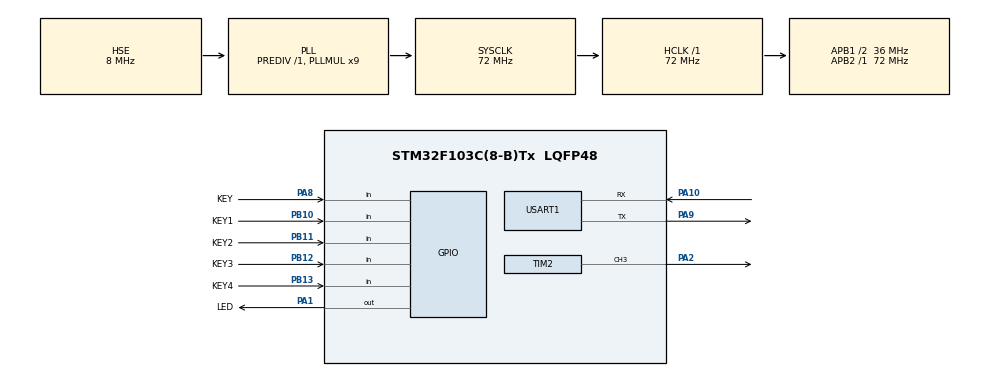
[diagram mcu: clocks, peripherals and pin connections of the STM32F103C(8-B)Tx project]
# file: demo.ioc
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Dma.Request0=TIM2_CH3
Dma.TIM2_CH3.0.Direction=DMA_MEMORY_TO_PERIPH
Dma.TIM2_CH3.0.Instance=DMA1_Channel1
Dma.TIM2_CH3.0.MemDataAlignment=DMA_MDATAALIGN_WORD
Dma.TIM2_CH3.0.MemInc=DMA_MINC_ENABLE
Dma.TIM2_CH3.0.Mode=DMA_NORMAL
Dma.TIM2_CH3.0.PeriphDataAlignment=DMA_PDATAALIGN_HALFWORD
Dma.TIM2_CH3.0.PeriphInc=DMA_PINC_DISABLE
Dma.TIM2_CH3.0.Priority=DMA_PRIORITY_LOW
Mcu.Family=STM32F1
Mcu.Name=STM32F103C(8-B)Tx
Mcu.Package=LQFP48
Mcu.UserConstants=ENC_TIM,htim4
NVIC.DMA1_Channel1_IRQn=true\:0\:0\:false\:false\:true\:false\:true\:true
NVIC.PriorityGroup=NVIC_PRIORITYGROUP_4
PA1.GPIO_Label=LED
PA1.GPIO_PuPd=GPIO_PULLUP
PA1.GPIO_Speed=GPIO_SPEED_FREQ_HIGH
PA1.Signal=GPIO_Output
PA10.Mode=Asynchronous
PA10.Signal=USART1_RX
PA13.Mode=Serial_Wire
PA13.Signal=SYS_JTMS-SWDIO
PA14.Mode=Serial_Wire
PA14.Signal=SYS_JTCK-SWCLK
PA2.Signal=S_TIM2_CH3
PA8.GPIO_Label=KEY
PA8.GPIO_PuPd=GPIO_PULLUP
PA8.Signal=GPIO_Input
PA9.Mode=Asynchronous
PA9.Signal=USART1_TX
PB10.GPIO_Label=KEY1
PB10.GPIO_PuPd=GPIO_PULLUP
PB10.Signal=GPIO_Input
PB11.GPIO_Label=KEY2
PB11.GPIO_PuPd=GPIO_PULLUP
PB11.Signal=GPIO_Input
PB12.GPIO_Label=KEY3
PB12.GPIO_PuPd=GPIO_PULLUP
PB12.Signal=GPIO_Input
PB13.GPIO_Label=KEY4
PB13.GPIO_PuPd=GPIO_PULLUP
PB13.Signal=GPIO_Input
PB9.GPIO_Speed=GPIO_SPEED_FREQ_HIGH
PB9.Signal=I2C1_SDA
PD0-OSC_IN.Mode=HSE-External-Oscillator
PD0-OSC_IN.Signal=RCC_OSC_IN
PD1-OSC_OUT.Mode=HSE-External-Oscillator
PD1-OSC_OUT.Signal=RCC_OSC_OUT
ProjectManager.HeapSize=0x800
ProjectManager.StackSize=0x800
ProjectManager.TargetToolchain=MDK-ARM V5
RCC.AHBFreq_Value=72000000
RCC.APB1CLKDivider=RCC_HCLK_DIV2
RCC.APB1Freq_Value=36000000
RCC.APB1TimFreq_Value=72000000
RCC.APB2Freq_Value=72000000
RCC.APB2TimFreq_Value=72000000
RCC.HCLKFreq_Value=72000000
RCC.PLLMUL=RCC_PLL_MUL9
RCC.PLLSourceVirtual=RCC_PLLSOURCE_HSE
RCC.SYSCLKFreq_VALUE=72000000
RCC.SYSCLKSource=RCC_SYSCLKSOURCE_PLLCLK
RCC.USBFreq_Value=48000000
RCC.USBPrescaler=RCC_USBCLKSOURCE_PLL_DIV1_5
SH.S_TIM2_CH3.0=TIM2_CH3,PWM Generation3 CH3
TIM2.AutoReloadPreload=TIM_AUTORELOAD_PRELOAD_DISABLE
TIM2.Channel-PWM\ Generation3\ CH3=TIM_CHANNEL_3
TIM2.Period=90-1
USART1.VirtualMode=VM_ASYNC
VP_RTC_VS_RTC_Activate.Mode=RTC_Enabled
board=custom

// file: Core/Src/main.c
/* USER CODE BEGIN Header */
/**
 ******************************************************************************
 * @file           : main.c
 * @brief          : Main program body
 ******************************************************************************
 * @attention
 *
 * Copyright (c) 2025 STMicroelectronics.
 * All rights reserved.
 *
 * This software is licensed under terms that can be found in the LICENSE file
 * in the root directory of this software component.
 * If no LICENSE file comes with this software, it is provided AS-IS.
 *
 ******************************************************************************
 */
/* USER CODE END Header */
#include "main.h"

/* USER CODE BEGIN Includes */
#include "ws2812.h"
/* USER CODE END Includes */

RTC_HandleTypeDef hrtc;

TIM_HandleTypeDef htim2;
DMA_HandleTypeDef hdma_tim2_ch3;

UART_HandleTypeDef huart1;

void SystemClock_Config(void);
static void MX_GPIO_Init(void);
static void MX_DMA_Init(void);
static void MX_USART1_UART_Init(void);
static void MX_RTC_Init(void);
static void MX_TIM2_Init(void);

int main(void)
{

  /* MCU Configuration--------------------------------------------------------*/

  /* Reset of all peripherals, Initializes the Flash interface and the Systick. */
  HAL_Init();

  /* Configure the system clock */
  SystemClock_Config();

  /* Initialize all configured peripherals */
  MX_GPIO_Init();
  MX_DMA_Init();
  MX_USART1_UART_Init();
  MX_RTC_Init();
  MX_TIM2_Init();

  /* Infinite loop */
  /* USER CODE BEGIN WHILE */
    while (1)
    {
        RGB_RED(Pixel_NUM);
        HAL_Delay(1000);
        RGB_GREEN(Pixel_NUM);
        HAL_Delay(1000);
        RGB_BLUE(Pixel_NUM);
        HAL_Delay(1000);
        RGB_WHITE(Pixel_NUM);
        HAL_Delay(1000);
    /* USER CODE END WHILE */

    }
}

void SystemClock_Config(void)
{
  RCC_OscInitTypeDef RCC_OscInitStruct = {0};
  RCC_ClkInitTypeDef RCC_ClkInitStruct = {0};
  RCC_PeriphCLKInitTypeDef PeriphClkInit = {0};

  /** Initializes the RCC Oscillators according to the specified parameters
  * in the RCC_OscInitTypeDef structure.
  */
  RCC_OscInitStruct.OscillatorType = RCC_OSCILLATORTYPE_LSI|RCC_OSCILLATORTYPE_HSE;
  RCC_OscInitStruct.HSEState = RCC_HSE_ON;
  RCC_OscInitStruct.HSEPredivValue = RCC_HSE_PREDIV_DIV1;
  RCC_OscInitStruct.HSIState = RCC_HSI_ON;
  RCC_OscInitStruct.LSIState = RCC_LSI_ON;
  RCC_OscInitStruct.PLL.PLLState = RCC_PLL_ON;
  RCC_OscInitStruct.PLL.PLLSource = RCC_PLLSOURCE_HSE;
  RCC_OscInitStruct.PLL.PLLMUL = RCC_PLL_MUL9;
  if (HAL_RCC_OscConfig(&RCC_OscInitStruct) != HAL_OK)
  {
    Error_Handler();
  }

  /** Initializes the CPU, AHB and APB buses clocks
  */
  RCC_ClkInitStruct.ClockType = RCC_CLOCKTYPE_HCLK|RCC_CLOCKTYPE_SYSCLK
                              |RCC_CLOCKTYPE_PCLK1|RCC_CLOCKTYPE_PCLK2;
  RCC_ClkInitStruct.SYSCLKSource = RCC_SYSCLKSOURCE_PLLCLK;
  RCC_ClkInitStruct.AHBCLKDivider = RCC_SYSCLK_DIV1;
  RCC_ClkInitStruct.APB1CLKDivider = RCC_HCLK_DIV2;
  RCC_ClkInitStruct.APB2CLKDivider = RCC_HCLK_DIV1;

  if (HAL_RCC_ClockConfig(&RCC_ClkInitStruct, FLASH_LATENCY_2) != HAL_OK)
  {
    Error_Handler();
  }
  PeriphClkInit.PeriphClockSelection = RCC_PERIPHCLK_RTC;
  PeriphClkInit.RTCClockSelection = RCC_RTCCLKSOURCE_LSI;
  if (HAL_RCCEx_PeriphCLKConfig(&PeriphClkInit) != HAL_OK)
  {
    Error_Handler();
  }
}

static void MX_RTC_Init(void)
{

  /** Initialize RTC Only
  */
  hrtc.Instance = RTC;
  hrtc.Init.AsynchPrediv = RTC_AUTO_1_SECOND;
  hrtc.Init.OutPut = RTC_OUTPUTSOURCE_ALARM;
  if (HAL_RTC_Init(&hrtc) != HAL_OK)
  {
    Error_Handler();
  }

}

static void MX_TIM2_Init(void)
{

  TIM_MasterConfigTypeDef sMasterConfig = {0};
  TIM_OC_InitTypeDef sConfigOC = {0};

  htim2.Instance = TIM2;
  htim2.Init.Prescaler = 0;
  htim2.Init.CounterMode = TIM_COUNTERMODE_UP;
  htim2.Init.Period = 90-1;
  htim2.Init.ClockDivision = TIM_CLOCKDIVISION_DIV1;
  htim2.Init.AutoReloadPreload = TIM_AUTORELOAD_PRELOAD_DISABLE;
  if (HAL_TIM_PWM_Init(&htim2) != HAL_OK)
  {
    Error_Handler();
  }
  sMasterConfig.MasterOutputTrigger = TIM_TRGO_RESET;
  sMasterConfig.MasterSlaveMode = TIM_MASTERSLAVEMODE_DISABLE;
  if (HAL_TIMEx_MasterConfigSynchronization(&htim2, &sMasterConfig) != HAL_OK)
  {
    Error_Handler();
  }
  sConfigOC.OCMode = TIM_OCMODE_PWM1;
  sConfigOC.Pulse = 0;
  sConfigOC.OCPolarity = TIM_OCPOLARITY_HIGH;
  sConfigOC.OCFastMode = TIM_OCFAST_DISABLE;
  if (HAL_TIM_PWM_ConfigChannel(&htim2, &sConfigOC, TIM_CHANNEL_3) != HAL_OK)
  {
    Error_Handler();
  }
  HAL_TIM_MspPostInit(&htim2);

}

static void MX_USART1_UART_Init(void)
{

  huart1.Instance = USART1;
  huart1.Init.BaudRate = 115200;
  huart1.Init.WordLength = UART_WORDLENGTH_8B;
  huart1.Init.StopBits = UART_STOPBITS_1;
  huart1.Init.Parity = UART_PARITY_NONE;
  huart1.Init.Mode = UART_MODE_TX_RX;
  huart1.Init.HwFlowCtl = UART_HWCONTROL_NONE;
  huart1.Init.OverSampling = UART_OVERSAMPLING_16;
  if (HAL_UART_Init(&huart1) != HAL_OK)
  {
    Error_Handler();
  }

}

static void MX_DMA_Init(void)
{

  /* DMA controller clock enable */
  __HAL_RCC_DMA1_CLK_ENABLE();

  /* DMA interrupt init */
  /* DMA1_Channel1_IRQn interrupt configuration */
  HAL_NVIC_SetPriority(DMA1_Channel1_IRQn, 0, 0);
  HAL_NVIC_EnableIRQ(DMA1_Channel1_IRQn);

}

static void MX_GPIO_Init(void)
{
  GPIO_InitTypeDef GPIO_InitStruct = {0};

  /* GPIO Ports Clock Enable */
  __HAL_RCC_GPIOD_CLK_ENABLE();
  __HAL_RCC_GPIOA_CLK_ENABLE();
  __HAL_RCC_GPIOB_CLK_ENABLE();

  /*Configure GPIO pin Output Level */
  HAL_GPIO_WritePin(LED_GPIO_Port, LED_Pin, GPIO_PIN_RESET);

  /*Configure GPIO pin : LED_Pin */
  GPIO_InitStruct.Pin = LED_Pin;
  GPIO_InitStruct.Mode = GPIO_MODE_OUTPUT_PP;
  GPIO_InitStruct.Pull = GPIO_PULLUP;
  GPIO_InitStruct.Speed = GPIO_SPEED_FREQ_HIGH;
  HAL_GPIO_Init(LED_GPIO_Port, &GPIO_InitStruct);

  /*Configure GPIO pins : KEY1_Pin KEY2_Pin KEY3_Pin KEY4_Pin */
  GPIO_InitStruct.Pin = KEY1_Pin|KEY2_Pin|KEY3_Pin|KEY4_Pin;
  GPIO_InitStruct.Mode = GPIO_MODE_INPUT;
  GPIO_InitStruct.Pull = GPIO_PULLUP;
  HAL_GPIO_Init(GPIOB, &GPIO_InitStruct);

  /*Configure GPIO pin : KEY_Pin */
  GPIO_InitStruct.Pin = KEY_Pin;
  GPIO_InitStruct.Mode = GPIO_MODE_INPUT;
  GPIO_InitStruct.Pull = GPIO_PULLUP;
  HAL_GPIO_Init(KEY_GPIO_Port, &GPIO_InitStruct);

  /*Configure GPIO pin : PB9 */
  GPIO_InitStruct.Pin = GPIO_PIN_9;
  GPIO_InitStruct.Mode = GPIO_MODE_AF_OD;
  GPIO_InitStruct.Speed = GPIO_SPEED_FREQ_HIGH;
  HAL_GPIO_Init(GPIOB, &GPIO_InitStruct);

  /*Configure peripheral I/O remapping */
  __HAL_AFIO_REMAP_I2C1_ENABLE();

}

void Error_Handler(void)
{
    __disable_irq();
    while (1)
    {
    }
}
